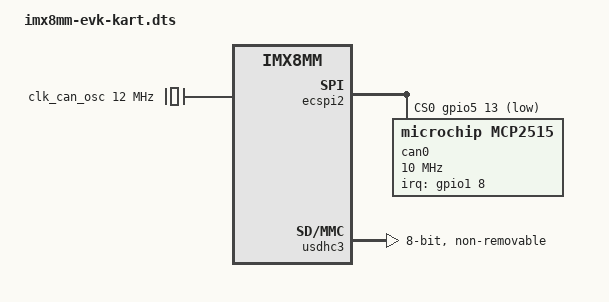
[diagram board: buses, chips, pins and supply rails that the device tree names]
// SPDX-License-Identifier: (GPL-2.0+ OR MIT)
/*
 * imx8mm-evk-kart.dts — kart 製品向け EVK バリアント: MCP2515 (SPI CAN) を追加
 *
 * ⚠️ ピン割り当ては暫定 (EVK スキャフォールド用)。
 * RPi5 では meta-raspberrypi の ENABLE_CAN=1 がファームウェアオーバーレイ
 * (mcp2515-can0) を適用していたが、i.MX にその機構は無く DTB に焼き込む。
 * XPI-iMX8MM の実機では 40 ピンヘッダの SPI がどの ECSPI インスタンスに
 * 割り当てられているか確認のうえ、このファイルのピン参照を差し替えること
 * (docs/imx8mm-migration-design.md の未確認事項 5)。
 *
 * 現在の暫定割り当て (imx8mm-lpddr4-evk):
 *   ECSPI2 専用パッド (SCLK/MOSI/MISO)、CS = ECSPI2_SS0 を GPIO5_IO13 で使用
 *   MCP2515 INT = GPIO1_IO08 (EVK の dtsi が未使用のパッド)
 *   発振子 12MHz (RPi5 の CAN_OSCILLATOR=12000000 と同じ HAT を想定)
 *
 * eMMC (usdhc3): mainline の EVK DT には microSD (usdhc2) しか無く、
 * EVK 実機に載っている eMMC が Linux から見えない。NXP ベンダツリー
 * (nxp-imx/linux-imx lf-6.6.y の imx8mm-evk.dts) の usdhc3 ノードを
 * ここに移植した (原本にある NAND_DATA06 の重複行は除去)。
 * imx8mm.dtsi のエイリアスは mmc2=usdhc3 なので /dev/mmcblk2 で安定する。
 */

#include "imx8mm-evk.dts"
#include <dt-bindings/interrupt-controller/irq.h>

/ {
	clk_can_osc: clock-can-osc {
		compatible = "fixed-clock";
		#clock-cells = <0>;
		clock-frequency = <12000000>;
		clock-output-names = "can_osc";
	};
};

&iomuxc {
	pinctrl_ecspi2: ecspi2grp {
		fsl,pins = <
			MX8MM_IOMUXC_ECSPI2_SCLK_ECSPI2_SCLK	0x82
			MX8MM_IOMUXC_ECSPI2_MOSI_ECSPI2_MOSI	0x82
			MX8MM_IOMUXC_ECSPI2_MISO_ECSPI2_MISO	0x82
		>;
	};

	pinctrl_ecspi2_cs: ecspi2csgrp {
		fsl,pins = <
			MX8MM_IOMUXC_ECSPI2_SS0_GPIO5_IO13	0x40000
		>;
	};

	pinctrl_can_int: canintgrp {
		fsl,pins = <
			/* 100k PU + hysteresis: MCP2515 INT はオープンドレイン相当 */
			MX8MM_IOMUXC_GPIO1_IO08_GPIO1_IO8	0x140
		>;
	};

	pinctrl_usdhc3: usdhc3grp {
		fsl,pins = <
			MX8MM_IOMUXC_NAND_WE_B_USDHC3_CLK	0x190
			MX8MM_IOMUXC_NAND_WP_B_USDHC3_CMD	0x1d0
			MX8MM_IOMUXC_NAND_DATA04_USDHC3_DATA0	0x1d0
			MX8MM_IOMUXC_NAND_DATA05_USDHC3_DATA1	0x1d0
			MX8MM_IOMUXC_NAND_DATA06_USDHC3_DATA2	0x1d0
			MX8MM_IOMUXC_NAND_DATA07_USDHC3_DATA3	0x1d0
			MX8MM_IOMUXC_NAND_RE_B_USDHC3_DATA4	0x1d0
			MX8MM_IOMUXC_NAND_CE2_B_USDHC3_DATA5	0x1d0
			MX8MM_IOMUXC_NAND_CE3_B_USDHC3_DATA6	0x1d0
			MX8MM_IOMUXC_NAND_CLE_USDHC3_DATA7	0x1d0
			MX8MM_IOMUXC_NAND_CE1_B_USDHC3_STROBE	0x190
		>;
	};

	pinctrl_usdhc3_100mhz: usdhc3-100mhzgrp {
		fsl,pins = <
			MX8MM_IOMUXC_NAND_WE_B_USDHC3_CLK	0x194
			MX8MM_IOMUXC_NAND_WP_B_USDHC3_CMD	0x1d4
			MX8MM_IOMUXC_NAND_DATA04_USDHC3_DATA0	0x1d4
			MX8MM_IOMUXC_NAND_DATA05_USDHC3_DATA1	0x1d4
			MX8MM_IOMUXC_NAND_DATA06_USDHC3_DATA2	0x1d4
			MX8MM_IOMUXC_NAND_DATA07_USDHC3_DATA3	0x1d4
			MX8MM_IOMUXC_NAND_RE_B_USDHC3_DATA4	0x1d4
			MX8MM_IOMUXC_NAND_CE2_B_USDHC3_DATA5	0x1d4
			MX8MM_IOMUXC_NAND_CE3_B_USDHC3_DATA6	0x1d4
			MX8MM_IOMUXC_NAND_CLE_USDHC3_DATA7	0x1d4
			MX8MM_IOMUXC_NAND_CE1_B_USDHC3_STROBE	0x194
		>;
	};

	pinctrl_usdhc3_200mhz: usdhc3-200mhzgrp {
		fsl,pins = <
			MX8MM_IOMUXC_NAND_WE_B_USDHC3_CLK	0x196
			MX8MM_IOMUXC_NAND_WP_B_USDHC3_CMD	0x1d6
			MX8MM_IOMUXC_NAND_DATA04_USDHC3_DATA0	0x1d6
			MX8MM_IOMUXC_NAND_DATA05_USDHC3_DATA1	0x1d6
			MX8MM_IOMUXC_NAND_DATA06_USDHC3_DATA2	0x1d6
			MX8MM_IOMUXC_NAND_DATA07_USDHC3_DATA3	0x1d6
			MX8MM_IOMUXC_NAND_RE_B_USDHC3_DATA4	0x1d6
			MX8MM_IOMUXC_NAND_CE2_B_USDHC3_DATA5	0x1d6
			MX8MM_IOMUXC_NAND_CE3_B_USDHC3_DATA6	0x1d6
			MX8MM_IOMUXC_NAND_CLE_USDHC3_DATA7	0x1d6
			MX8MM_IOMUXC_NAND_CE1_B_USDHC3_STROBE	0x196
		>;
	};
};

&ecspi2 {
	#address-cells = <1>;
	#size-cells = <0>;
	pinctrl-names = "default";
	pinctrl-0 = <&pinctrl_ecspi2>, <&pinctrl_ecspi2_cs>;
	cs-gpios = <&gpio5 13 GPIO_ACTIVE_LOW>;
	status = "okay";

	can0: mcp2515@0 {
		compatible = "microchip,mcp2515";
		reg = <0>;
		pinctrl-names = "default";
		pinctrl-0 = <&pinctrl_can_int>;
		clocks = <&clk_can_osc>;
		interrupt-parent = <&gpio1>;
		interrupts = <8 IRQ_TYPE_LEVEL_LOW>;
		/* MCP2515 の SPI 上限 10MHz */
		spi-max-frequency = <10000000>;
	};
};

/* EVK 実機の eMMC (16GB)。NXP lf-6.6.y の imx8mm-evk.dts から移植。 */
&usdhc3 {
	assigned-clocks = <&clk IMX8MM_CLK_USDHC3_ROOT>;
	assigned-clock-rates = <400000000>;
	pinctrl-names = "default", "state_100mhz", "state_200mhz";
	pinctrl-0 = <&pinctrl_usdhc3>;
	pinctrl-1 = <&pinctrl_usdhc3_100mhz>;
	pinctrl-2 = <&pinctrl_usdhc3_200mhz>;
	bus-width = <8>;
	non-removable;
	status = "okay";
};
